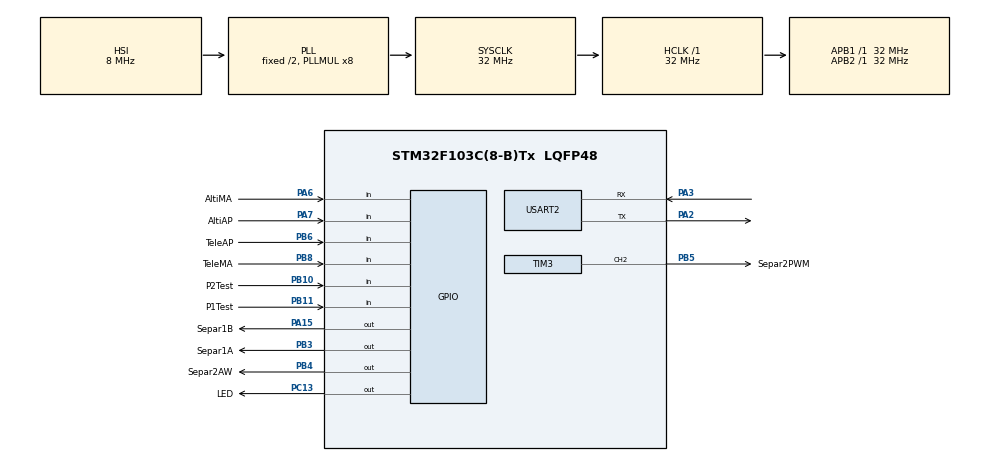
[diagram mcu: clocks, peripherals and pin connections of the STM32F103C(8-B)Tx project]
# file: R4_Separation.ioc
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Mcu.Family=STM32F1
PB10.GPIO_PuPd=GPIO_PULLUP
Dma.USART2_TX.1.MemInc=DMA_MINC_ENABLE
PA6.GPIO_Label=AltiMA
PB6.GPIO_Label=TeleAP
PB11.GPIO_PuPd=GPIO_PULLUP
PB11.Signal=GPIO_Input
RCC.SYSCLKSource=RCC_SYSCLKSOURCE_PLLCLK
ProjectManager.StackSize=0x400
PD1-OSC_OUT.Signal=RCC_OSC_OUT
PA15.GPIO_Label=Separ1B
Dma.USART2_RX.0.Priority=DMA_PRIORITY_LOW
Dma.USART2_RX.0.PeriphDataAlignment=DMA_PDATAALIGN_BYTE
RCC.HCLKFreq_Value=32000000
RCC.APB2TimFreq_Value=32000000
TIM3.Period=999
PB6.Signal=GPIO_Input
Dma.USART2_TX.1.Mode=DMA_NORMAL
RCC.AHBFreq_Value=32000000
RCC.PLLMUL=RCC_PLL_MUL8
PA6.GPIO_PuPd=GPIO_PULLUP
Dma.USART2_RX.0.MemDataAlignment=DMA_MDATAALIGN_BYTE
PC13-TAMPER-RTC.PinState=GPIO_PIN_SET
PA14.Mode=Serial_Wire
Dma.USART2_TX.1.Instance=DMA1_Channel7
TIM3.Prescaler=639
Dma.USART2_RX.0.Instance=DMA1_Channel6
Mcu.Package=LQFP48
PA6.Signal=GPIO_Input
Dma.USART2_RX.0.PeriphInc=DMA_PINC_DISABLE
USART2.VirtualMode=VM_ASYNC
PA15.Signal=GPIO_Output
PB5.GPIO_Label=Separ2PWM
Dma.Request1=USART2_TX
RCC.APB1TimFreq_Value=32000000
Dma.Request0=USART2_RX
VP_TIM3_VS_ClockSourceINT.Mode=Internal
PB4.Signal=GPIO_Output
PA3.Signal=USART2_RX
PB3.GPIO_Label=Separ1A
NVIC.DMA1_Channel6_IRQn=true\:0\:0\:false\:true\:true\:1\:false\:true
Dma.USART2_TX.1.Priority=DMA_PRIORITY_LOW
PD1-OSC_OUT.Mode=HSE-External-Oscillator
TIM3.AutoReloadPreload=TIM_AUTORELOAD_PRELOAD_ENABLE
PB6.GPIO_PuPd=GPIO_PULLUP
PB11.GPIO_Label=P1Test
Dma.USART2_RX.0.Direction=DMA_PERIPH_TO_MEMORY
PC13-TAMPER-RTC.Signal=GPIO_Output
PD0-OSC_IN.Signal=RCC_OSC_IN
Dma.USART2_TX.1.PeriphDataAlignment=DMA_PDATAALIGN_BYTE
NVIC.USART2_IRQn=true\:1\:0\:true\:true\:true\:3\:true\:true
Dma.USART2_RX.0.Mode=DMA_NORMAL
PA13.Signal=SYS_JTMS-SWDIO
PA3.Mode=Asynchronous
PB8.GPIO_Label=TeleMA
ProjectManager.TargetToolchain=STM32CubeIDE
PB10.GPIO_Label=P2Test
RCC.USBFreq_Value=32000000
PA7.GPIO_PuPd=GPIO_PULLUP
PD0-OSC_IN.Mode=HSE-External-Oscillator
PB10.Signal=GPIO_Input
SH.S_TIM3_CH2.0=TIM3_CH2,PWM Generation2 CH2
Dma.USART2_TX.1.PeriphInc=DMA_PINC_DISABLE
board=custom
PC13-TAMPER-RTC.GPIO_Label=LED
NVIC.TIM3_IRQn=true\:1\:0\:true\:false\:true\:true\:true
Dma.USART2_TX.1.Direction=DMA_MEMORY_TO_PERIPH
RCC.APB2Freq_Value=32000000
PB4.GPIO_Label=Separ2AW
PA13.Mode=Serial_Wire
Mcu.Name=STM32F103C(8-B)Tx
Dma.USART2_RX.0.MemInc=DMA_MINC_ENABLE
PA2.Signal=USART2_TX
PB3.Signal=GPIO_Output
RCC.SYSCLKFreq_VALUE=32000000
PC13-TAMPER-RTC.GPIO_ModeDefaultOutputPP=GPIO_MODE_OUTPUT_PP
PB5.Signal=S_TIM3_CH2
PA7.GPIO_Label=AltiAP
PA14.Signal=SYS_JTCK-SWCLK
ProjectManager.HeapSize=0x200
NVIC.PriorityGroup=NVIC_PRIORITYGROUP_4
TIM3.Channel-PWM\ Generation2\ CH2=TIM_CHANNEL_2
PA2.Mode=Asynchronous
PB8.Signal=GPIO_Input
NVIC.DMA1_Channel7_IRQn=true\:0\:0\:true\:true\:true\:2\:false\:true
Dma.USART2_TX.1.MemDataAlignment=DMA_MDATAALIGN_BYTE
RCC.APB1Freq_Value=32000000
PA7.Signal=GPIO_Input

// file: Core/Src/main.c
/* USER CODE BEGIN Header */
/**
 ******************************************************************************
 * @file           : main.c
 * @brief          : Main program body
 ******************************************************************************
 * @attention
 *
 * <h2><center>&copy; Copyright (c) 2021 STMicroelectronics.
 * All rights reserved.</center></h2>
 *
 * This software component is licensed by ST under BSD 3-Clause license,
 * the "License"; You may not use this file except in compliance with the
 * License. You may obtain a copy of the License at:
 *                        opensource.org/licenses/BSD-3-Clause
 *
 ******************************************************************************
 */
/* USER CODE END Header */
#include "main.h"
#include "dma.h"
#include "tim.h"
#include "usart.h"
#include "gpio.h"

/* USER CODE BEGIN Includes */

#include "Separation.h"

/* USER CODE END Includes */

void SystemClock_Config(void);
static void MX_NVIC_Init(void);

int main(void)
{

  /* MCU Configuration--------------------------------------------------------*/

  /* Reset of all peripherals, Initializes the Flash interface and the Systick. */
  HAL_Init();

  /* Configure the system clock */
  SystemClock_Config();

  /* Initialize all configured peripherals */
  MX_GPIO_Init();
  MX_DMA_Init();
  MX_TIM3_Init();
  MX_USART2_UART_Init();

  /* Initialize interrupts */
  MX_NVIC_Init();
  /* USER CODE BEGIN 2 */

	__HAL_UART_ENABLE_IT(&huart2, UART_IT_IDLE);
	HAL_UART_Receive_DMA(&huart2, (uint8_t*) uartRxTab, ARRAY_SIZE);

	HAL_TIM_PWM_Start(&htim3, SEPAR_2_PWM_CHANNEL);

	// Tutaj dodać odpowiednie ustawienie serwa
	//__HAL_TIM_SET_COMPARE(&htim3, SEPAR_2_PWM_CHANNEL, valu);

	currentState = INIT;

	while (currentState == INIT) {
		initLoop();
	}

	while (currentState == FLIGHT) {
		flightLoop();
	}

	stopAll();

  /* USER CODE END 2 */

  /* Infinite loop */
	while (1) {

	}
}

void SystemClock_Config(void)
{
  RCC_OscInitTypeDef RCC_OscInitStruct = {0};
  RCC_ClkInitTypeDef RCC_ClkInitStruct = {0};

  /** Initializes the RCC Oscillators according to the specified parameters
  * in the RCC_OscInitTypeDef structure.
  */
  RCC_OscInitStruct.OscillatorType = RCC_OSCILLATORTYPE_HSI;
  RCC_OscInitStruct.HSIState = RCC_HSI_ON;
  RCC_OscInitStruct.HSICalibrationValue = RCC_HSICALIBRATION_DEFAULT;
  RCC_OscInitStruct.PLL.PLLState = RCC_PLL_ON;
  RCC_OscInitStruct.PLL.PLLSource = RCC_PLLSOURCE_HSI_DIV2;
  RCC_OscInitStruct.PLL.PLLMUL = RCC_PLL_MUL8;
  if (HAL_RCC_OscConfig(&RCC_OscInitStruct) != HAL_OK)
  {
    Error_Handler();
  }
  /** Initializes the CPU, AHB and APB buses clocks
  */
  RCC_ClkInitStruct.ClockType = RCC_CLOCKTYPE_HCLK|RCC_CLOCKTYPE_SYSCLK
                              |RCC_CLOCKTYPE_PCLK1|RCC_CLOCKTYPE_PCLK2;
  RCC_ClkInitStruct.SYSCLKSource = RCC_SYSCLKSOURCE_PLLCLK;
  RCC_ClkInitStruct.AHBCLKDivider = RCC_SYSCLK_DIV1;
  RCC_ClkInitStruct.APB1CLKDivider = RCC_HCLK_DIV1;
  RCC_ClkInitStruct.APB2CLKDivider = RCC_HCLK_DIV1;

  if (HAL_RCC_ClockConfig(&RCC_ClkInitStruct, FLASH_LATENCY_1) != HAL_OK)
  {
    Error_Handler();
  }
}

/**
  * @brief NVIC Configuration.
  * @retval None
  */
static void MX_NVIC_Init(void)
{
  /* DMA1_Channel6_IRQn interrupt configuration */
  HAL_NVIC_SetPriority(DMA1_Channel6_IRQn, 0, 0);
  HAL_NVIC_EnableIRQ(DMA1_Channel6_IRQn);
  /* DMA1_Channel7_IRQn interrupt configuration */
  HAL_NVIC_SetPriority(DMA1_Channel7_IRQn, 0, 0);
  HAL_NVIC_EnableIRQ(DMA1_Channel7_IRQn);
  /* USART2_IRQn interrupt configuration */
  HAL_NVIC_SetPriority(USART2_IRQn, 1, 0);
  HAL_NVIC_EnableIRQ(USART2_IRQn);
}

void Error_Handler(void)
{
	__disable_irq();
	while (1) {
	}
}

/************************ (C) COPYRIGHT STMicroelectronics *****END OF FILE****/
